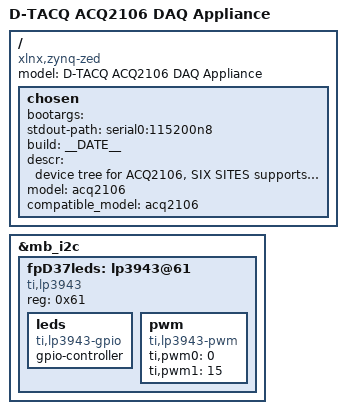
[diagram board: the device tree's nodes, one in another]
/*
 * Copyright (C) 2013 D-TACQ Solutions Ltd - http://www.d-tacq.com/
 *
 * This program is free software; you can redistribute it and/or modify
 * it under the terms of the GNU General Public License version 2 as
 * published by the Free Software Foundation.
 */

/dts-v1/;
#include "acq2106_common.dtsi"

/ {
	model = "D-TACQ ACQ2106 DAQ Appliance";
	compatible = "xlnx,zynq-zed", "xlnx,zynq-7000";

	chosen {
		bootargs = "";
		stdout-path = "serial0:115200n8";
		build="__DATE__";	
		descr="device tree for ACQ2106, SIX SITES supports MGT-DRAM, D37FP";
		model="acq2106";
		compatible_model="acq2106";		
	};
};


&mb_i2c {
	fpD37leds: lp3943@61 {
		compatible = "ti,lp3943";
		reg = <0x61>;
		leds {
			compatible = "ti,lp3943-gpio";
			gpio-controller;
			#gpio-cells = <16>;
		};
		pwm {
			compatible = "ti,lp3943-pwm";
			#pwm-cells = <2>;
			ti,pwm0 = <0>; /* LED0=FAN */
			ti,pwm1 = <15>; /* ZFAN */
		};						
	};	
};
